AUTOSAR XML (schema 4-0-3)
package /ComponentTypes
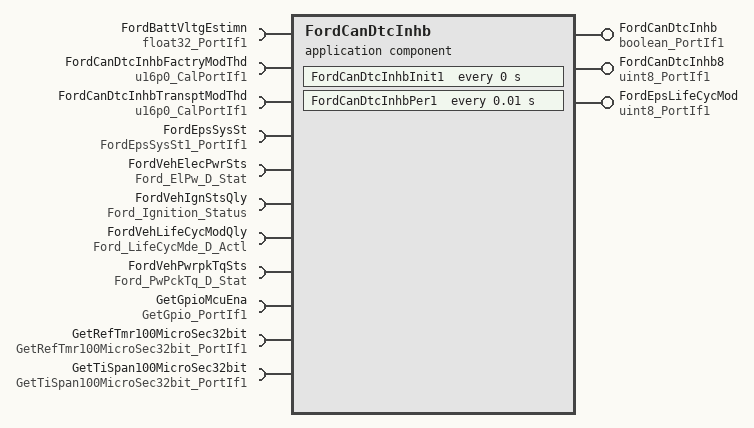
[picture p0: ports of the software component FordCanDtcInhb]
  application sw component type FordCanDtcInhb
    provide port FordCanDtcInhb: nonqueued-sender-com-spec{data-element=Logl, init-value=0}, provided-interface=boolean_PortIf1
    provide port FordCanDtcInhb8: nonqueued-sender-com-spec{data-element=Val, init-value=1}, provided-interface=uint8_PortIf1
    provide port FordEpsLifeCycMod: nonqueued-sender-com-spec{data-element=Val, init-value=0}, provided-interface=uint8_PortIf1
    11 x require port:
      FordBattVltgEstimn: nonqueued-receiver-com-spec{data-element=Val, filter=data-filter-type=ALWAYS, init-value=6}, required-interface=float32_PortIf1
      FordCanDtcInhbFactryModThd: parameter-require-com-spec{init-value=0, parameter=Val}, required-interface=u16p0_CalPortIf1
      FordCanDtcInhbTransptModThd: parameter-require-com-spec{init-value=0, parameter=Val}, required-interface=u16p0_CalPortIf1
      FordEpsSysSt: nonqueued-receiver-com-spec{data-element=Val, filter=data-filter-type=ALWAYS, init-value=0}, required-interface=FordEpsSysSt1_PortIf1
      FordVehElecPwrSts: nonqueued-receiver-com-spec{data-element=Ford_ElPw_D_Stat, filter=data-filter-type=ALWAYS, init-value=0}, required-interface=Ford_ElPw_D_Stat
      FordVehIgnStsQly: nonqueued-receiver-com-spec{data-element=Ford_Ignition_Status, filter=data-filter-type=ALWAYS, init-value=0}, required-interface=Ford_Ignition_Status
      FordVehLifeCycModQly: nonqueued-receiver-com-spec{data-element=Ford_LifeCycMde_D_Actl, filter=data-filter-type=ALWAYS, init-value=0}, required-interface=Ford_LifeCycMde_D_Actl
      FordVehPwrpkTqSts: nonqueued-receiver-com-spec{data-element=Ford_PwPckTq_D_Stat, filter=data-filter-type=ALWAYS, init-value=0}, required-interface=Ford_PwPckTq_D_Stat
      GetGpioMcuEna: client-com-spec=Oper, required-interface=GetGpio_PortIf1
      GetRefTmr100MicroSec32bit: client-com-spec=Oper, required-interface=GetRefTmr100MicroSec32bit_PortIf1
      GetTiSpan100MicroSec32bit: client-com-spec=Oper, required-interface=GetTiSpan100MicroSec32bit_PortIf1
    behavior FordCanDtcInhb_InternalBehavior
      ar-typed-per-instance-memorys:
        6 x data, all with sw-calibration-access=READ-ONLY:
          CanDtcInhbRefTi: type=uint32
          EpsFactryModRefTi: type=uint32
          EpsLifeCycModPrev: type=boolean
          EpsLifeCycModRefTi: type=uint32
          EpsTransptModRefTi: type=uint32
          FordReqdEpsLifeCycModPrev: type=FordEpsLifeCycMod1
      timing event FordCanDtcInhb_InitEvent: start-on-event=FordCanDtcInhbInit1, period=0
      timing event TMT_FordCanDtcInhbPer1: start-on-event=FordCanDtcInhbPer1, period=0.01
      port-api-options:
        enable-take-address=false, indirect-api=false, port=FordBattVltgEstimn
        enable-take-address=false, indirect-api=false, port=FordCanDtcInhb
        enable-take-address=false, indirect-api=false, port=FordCanDtcInhb8
        enable-take-address=false, indirect-api=false, port=FordCanDtcInhbFactryModThd
        enable-take-address=false, indirect-api=false, port=FordCanDtcInhbTransptModThd
        enable-take-address=false, indirect-api=false, port=FordEpsLifeCycMod
        enable-take-address=false, indirect-api=false, port=FordEpsSysSt
        enable-take-address=false, indirect-api=false, port=FordVehElecPwrSts
        enable-take-address=false, indirect-api=false, port=FordVehIgnStsQly
        enable-take-address=false, indirect-api=false, port=FordVehLifeCycModQly
        enable-take-address=false, indirect-api=false, port=FordVehPwrpkTqSts
        enable-take-address=false, indirect-api=false, port=GetGpioMcuEna
        enable-take-address=false, indirect-api=false, port=GetRefTmr100MicroSec32bit
        enable-take-address=false, indirect-api=false, port=GetTiSpan100MicroSec32bit
      runnable FordCanDtcInhbInit1
        sync call SC_GetRefTmr100MicroSec32bit_Oper: operation=GetRefTmr100MicroSec32bit.Oper, timeout=0
      runnable FordCanDtcInhbPer1
        data-receive-point-by-arguments:
          6 x access:
            REC_FordBattVltgEstimn_Val: accessed-variable=FordBattVltgEstimn.Val
            REC_FordEpsSysSt_Val: accessed-variable=FordEpsSysSt.Val
            REC_FordVehElecPwrSts_Ford_ElPw_D_Stat: accessed-variable=FordVehElecPwrSts.Ford_ElPw_D_Stat
            REC_FordVehIgnStsQly_Ford_Ignition_Status: accessed-variable=FordVehIgnStsQly.Ford_Ignition_Status
            REC_FordVehLifeCycModQly_Ford_LifeCycMde_D_Actl: accessed-variable=FordVehLifeCycModQly.Ford_LifeCycMde_D_Actl
            REC_FordVehPwrpkTqSts_Ford_PwPckTq_D_Stat: accessed-variable=FordVehPwrpkTqSts.Ford_PwPckTq_D_Stat
        data-send-points:
          access SEND_FordCanDtcInhb_Logl: accessed-variable=FordCanDtcInhb.Logl
          access SEND_FordCanDtcInhb_Val: accessed-variable=FordCanDtcInhb8.Val
          access SEND_FordEpsLifeCycMod_Val: accessed-variable=FordEpsLifeCycMod.Val
        sync call SC_GetGpioMcuEna_Oper: operation=GetGpioMcuEna.Oper, timeout=0
        sync call SC_GetRefTmr100MicroSec32bit_Oper: operation=GetRefTmr100MicroSec32bit.Oper, timeout=0
        sync call SC_GetTiSpan100MicroSec32bit_Oper: operation=GetTiSpan100MicroSec32bit.Oper, timeout=0
  swc implementation FordCanDtcInhb_Implementation: behavior=FordCanDtcInhb_InternalBehavior
    code-descriptors:
      code Default: artifact-descriptors=autosar-engineering-object={short-label=Default, category=SWSRC}
